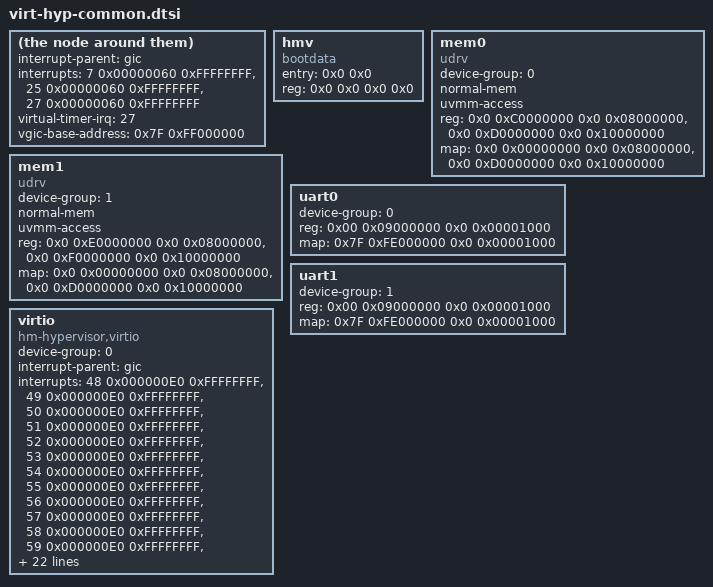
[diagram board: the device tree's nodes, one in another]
interrupt-parent = <&gic>;
interrupts =	< 7 0x00000060 0xFFFFFFFF>,
		<25 0x00000060 0xFFFFFFFF>,
		<27 0x00000060 0xFFFFFFFF>;

virtual-timer-irq = <27>;
vgic-base-address = <0x7F 0xFF000000>;

hmv {
	compatible = "bootdata";
	/* filled by bootloader */
	entry = <0x0 0x0>;
	reg = <0x0 0x0 0x0 0x0>;
};

mem0 {
	device-group = <0>;
	compatible = "udrv";
	normal-mem;
	uvmm-access;
	reg = <0x0 0xC0000000 0x0 0x08000000>,
	      <0x0 0xD0000000 0x0 0x10000000>;
	map = <0x0 0x00000000 0x0 0x08000000>,
	      <0x0 0xD0000000 0x0 0x10000000>;
};

mem1 {
	device-group = <1>;
	compatible = "udrv";
	normal-mem;
	uvmm-access;
	reg = <0x0 0xE0000000 0x0 0x08000000>,
	      <0x0 0xF0000000 0x0 0x10000000>;
	map = <0x0 0x00000000 0x0 0x08000000>,
	      <0x0 0xD0000000 0x0 0x10000000>;
};

uart0 {
	device-group = <0>;
	reg = <0x00 0x09000000 0x0 0x00001000>;
	map = <0x7F 0xFE000000 0x0 0x00001000>;
};

uart1 {
	device-group = <1>;
	reg = <0x00 0x09000000 0x0 0x00001000>;
	map = <0x7F 0xFE000000 0x0 0x00001000>;
};

virtio {
	device-group = <0>;
	compatible = "hm-hypervisor,virtio";
	interrupt-parent = <&gic>;
	interrupts =	<48 0x000000E0 0xFFFFFFFF>,
			<49 0x000000E0 0xFFFFFFFF>,
			<50 0x000000E0 0xFFFFFFFF>,
			<51 0x000000E0 0xFFFFFFFF>,
			<52 0x000000E0 0xFFFFFFFF>,
			<53 0x000000E0 0xFFFFFFFF>,
			<54 0x000000E0 0xFFFFFFFF>,
			<55 0x000000E0 0xFFFFFFFF>,
			<56 0x000000E0 0xFFFFFFFF>,
			<57 0x000000E0 0xFFFFFFFF>,
			<58 0x000000E0 0xFFFFFFFF>,
			<59 0x000000E0 0xFFFFFFFF>,
			<60 0x000000E0 0xFFFFFFFF>,
			<61 0x000000E0 0xFFFFFFFF>,
			<62 0x000000E0 0xFFFFFFFF>,
			<63 0x000000E0 0xFFFFFFFF>,
			<64 0x000000E0 0xFFFFFFFF>,
			<65 0x000000E0 0xFFFFFFFF>,
			<66 0x000000E0 0xFFFFFFFF>,
			<67 0x000000E0 0xFFFFFFFF>,
			<68 0x000000E0 0xFFFFFFFF>,
			<69 0x000000E0 0xFFFFFFFF>,
			<70 0x000000E0 0xFFFFFFFF>,
			<71 0x000000E0 0xFFFFFFFF>,
			<72 0x000000E0 0xFFFFFFFF>,
			<73 0x000000E0 0xFFFFFFFF>,
			<74 0x000000E0 0xFFFFFFFF>,
			<75 0x000000E0 0xFFFFFFFF>,
			<76 0x000000E0 0xFFFFFFFF>,
			<77 0x000000E0 0xFFFFFFFF>,
			<78 0x000000E0 0xFFFFFFFF>,
			<79 0x000000E0 0xFFFFFFFF>;
	reg = <0x0 0x0A000000 0x0 0x00004000>;
	map = <0x0 0x0A000000 0x0 0x00004000>;
};
